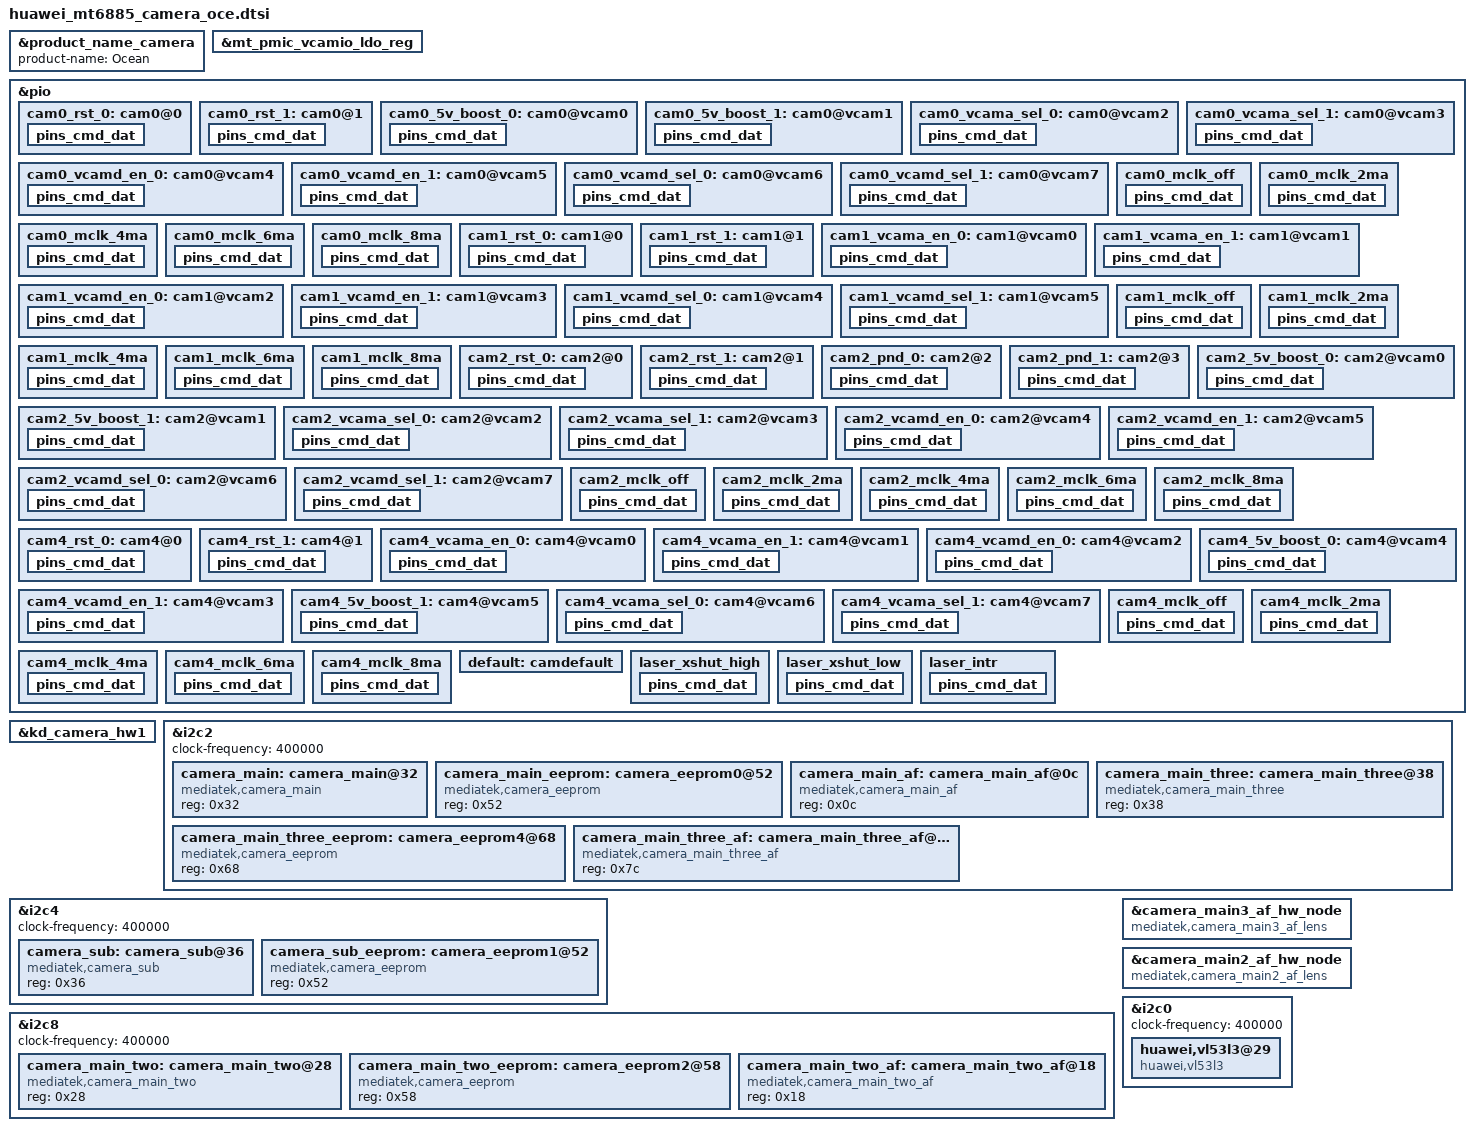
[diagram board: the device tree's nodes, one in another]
/*
 * Copyright (c) 2020 MediaTek Inc.
 *
 * This program is free software; you can redistribute it and/or modify
 * it under the terms of the GNU General Public License version 2 as
 * published by the Free Software Foundation.
 *
 * This program is distributed in the hope that it will be useful,
 * but WITHOUT ANY WARRANTY; without even the implied warranty of
 * MERCHANTABILITY or FITNESS FOR A PARTICULAR PURPOSE.  See the
 * GNU General Public License for more details.
 */

&product_name_camera {
	product-name = "Ocean";
};

&mt_pmic_vcamio_ldo_reg {
	regulator-min-microvolt = <1700000>;
	regulator-max-microvolt = <1900000>;
	regulator-default-on = <2>; /* 0:skip, 1: off, 2:on */
	regulator-boot-on;
};

/* CAMERA GPIO standardization */
&pio {
	/* Main Cam: cam0 GPIOs begin */
	cam0_rst_0: cam0@0 {
		pins_cmd_dat {
			pinmux = <PINMUX_GPIO143__FUNC_GPIO143>;
			slew-rate = <1>;
			output-low;
		};
	};
	cam0_rst_1: cam0@1 {
		pins_cmd_dat {
			pinmux = <PINMUX_GPIO143__FUNC_GPIO143>;
			slew-rate = <1>;
			output-high;
		};
	};

	/* bst_5v */
	cam0_5v_boost_0: cam0@vcam0 {
		pins_cmd_dat {
			pinmux = <PINMUX_GPIO81__FUNC_GPIO81>;
			slew-rate = <1>;
			output-low;
		};
	};
	cam0_5v_boost_1: cam0@vcam1 {
		pins_cmd_dat {
			pinmux = <PINMUX_GPIO81__FUNC_GPIO81>;
			slew-rate = <1>;
			output-high;
		};
	};

	cam0_vcama_sel_0: cam0@vcam2 {
		pins_cmd_dat {
			pinmux = <PINMUX_GPIO134__FUNC_GPIO134>;
			slew-rate = <1>;
			output-low;
		};
	};

	cam0_vcama_sel_1: cam0@vcam3 {
		pins_cmd_dat {
			pinmux = <PINMUX_GPIO134__FUNC_GPIO134>;
			slew-rate = <1>;
			output-high;
		};
	};

	cam0_vcamd_en_0: cam0@vcam4 {
		pins_cmd_dat {
			pinmux = <PINMUX_GPIO135__FUNC_GPIO135>;
			slew-rate = <1>;
			output-low;
		};
	};
	cam0_vcamd_en_1: cam0@vcam5 {
		pins_cmd_dat {
			pinmux = <PINMUX_GPIO135__FUNC_GPIO135>;
			slew-rate = <1>;
			output-high;
		};
	};

	cam0_vcamd_sel_0: cam0@vcam6 {
		pins_cmd_dat {
			pinmux = <PINMUX_GPIO138__FUNC_GPIO138>;
			slew-rate = <1>;
			output-low;
		};
	};
	cam0_vcamd_sel_1: cam0@vcam7 {
		pins_cmd_dat {
			pinmux = <PINMUX_GPIO138__FUNC_GPIO138>;
			slew-rate = <1>;
			output-high;
		};
	};

	cam0_mclk_off: cam0_mclk_off {
		pins_cmd_dat {
			pinmux = <PINMUX_GPIO149__FUNC_GPIO149>;
			drive-strength = <1>;
		};
	};
	cam0_mclk_2ma: cam0_mclk_2ma {
		pins_cmd_dat {
			pinmux = <PINMUX_GPIO149__FUNC_CMMCLK0>;
			drive-strength = <0>;
		};
	};
	cam0_mclk_4ma: cam0_mclk_4ma {
		pins_cmd_dat {
			pinmux = <PINMUX_GPIO149__FUNC_CMMCLK0>;
			drive-strength = <1>;
		};
	};
	cam0_mclk_6ma: cam0_mclk_6ma {
		pins_cmd_dat {
			pinmux = <PINMUX_GPIO149__FUNC_CMMCLK0>;
			drive-strength = <2>;
		};
	};
	cam0_mclk_8ma: cam0_mclk_8ma {
		pins_cmd_dat {
			pinmux = <PINMUX_GPIO149__FUNC_CMMCLK0>;
			drive-strength = <3>;
		};
	};
	/* Main Cam: cam0 GPIOs end */

	/* Sub(front) Cam: cam1 GPIOs begin */
	cam1_rst_0: cam1@0 {
		pins_cmd_dat {
			pinmux = <PINMUX_GPIO131__FUNC_GPIO131>;
			slew-rate = <1>;
			output-low;
		};
	};
	cam1_rst_1: cam1@1 {
		pins_cmd_dat {
			pinmux = <PINMUX_GPIO131__FUNC_GPIO131>;
			slew-rate = <1>;
			output-high;
		};
	};

	cam1_vcama_en_0: cam1@vcam0 {
		pins_cmd_dat {
			pinmux = <PINMUX_GPIO130__FUNC_GPIO130>;
			slew-rate = <1>;
			output-low;
		};
	};
	cam1_vcama_en_1: cam1@vcam1 {
		pins_cmd_dat {
			pinmux = <PINMUX_GPIO130__FUNC_GPIO130>;
			slew-rate = <1>;
			output-high;
		};
	};

	cam1_vcamd_en_0: cam1@vcam2 {
		pins_cmd_dat {
			pinmux = <PINMUX_GPIO134__FUNC_GPIO134>;
			slew-rate = <1>;
			output-low;
		};
	};
	cam1_vcamd_en_1: cam1@vcam3 {
		pins_cmd_dat {
			pinmux = <PINMUX_GPIO134__FUNC_GPIO134>;
			slew-rate = <1>;
			output-high;
		};
	};

	cam1_vcamd_sel_0: cam1@vcam4 {
		pins_cmd_dat {
			pinmux = <PINMUX_GPIO138__FUNC_GPIO138>;
			slew-rate = <1>;
			output-low;
		};
	};
	cam1_vcamd_sel_1: cam1@vcam5 {
		pins_cmd_dat {
			pinmux = <PINMUX_GPIO138__FUNC_GPIO138>;
			slew-rate = <1>;
			output-high;
		};
	};

	cam1_mclk_off: cam1_mclk_off {
		pins_cmd_dat {
			pinmux = <PINMUX_GPIO136__FUNC_GPIO136>;
			drive-strength = <1>;
		};
	};
	cam1_mclk_2ma: cam1_mclk_2ma {
		pins_cmd_dat {
			pinmux = <PINMUX_GPIO136__FUNC_CMMCLK3>;
			drive-strength = <0>;
		};
	};
	cam1_mclk_4ma: cam1_mclk_4ma {
		pins_cmd_dat {
			pinmux = <PINMUX_GPIO136__FUNC_CMMCLK3>;
			drive-strength = <1>;
		};
	};
	cam1_mclk_6ma: cam1_mclk_6ma {
		pins_cmd_dat {
			pinmux = <PINMUX_GPIO136__FUNC_CMMCLK3>;
			drive-strength = <2>;
		};
	};
	cam1_mclk_8ma: cam1_mclk_8ma {
		pins_cmd_dat {
			pinmux = <PINMUX_GPIO136__FUNC_CMMCLK3>;
			drive-strength = <3>;
		};
	};
	/* Sub(front) Cam: cam1 GPIOs end */

	/* Main2(wide) Cam: cam2 GPIOs begin */
	cam2_rst_0: cam2@0 {
		pins_cmd_dat {
			pinmux = <PINMUX_GPIO144__FUNC_GPIO144>;
			slew-rate = <1>;
			output-low;
		};
	};
	cam2_rst_1: cam2@1 {
		pins_cmd_dat {
			pinmux = <PINMUX_GPIO144__FUNC_GPIO144>;
			slew-rate = <1>;
			output-high;
		};
	};

	cam2_pnd_0: cam2@2 {
		pins_cmd_dat {
			pinmux = <PINMUX_GPIO130__FUNC_GPIO130>;
			slew-rate = <1>;
			output-low;
		};
	};
	cam2_pnd_1: cam2@3 {
		pins_cmd_dat {
			pinmux = <PINMUX_GPIO130__FUNC_GPIO130>;
			slew-rate = <1>;
			output-high;
		};
	};

	cam2_5v_boost_0: cam2@vcam0 {
		pins_cmd_dat {
			pinmux = <PINMUX_GPIO81__FUNC_GPIO81>;
			slew-rate = <1>;
			output-low;
		};
	};
	cam2_5v_boost_1: cam2@vcam1 {
		pins_cmd_dat {
			pinmux = <PINMUX_GPIO81__FUNC_GPIO81>;
			slew-rate = <1>;
			output-high;
		};
	};

	cam2_vcama_sel_0: cam2@vcam2 {
		pins_cmd_dat {
			pinmux = <PINMUX_GPIO137__FUNC_GPIO137>;
			slew-rate = <1>;
			output-low;
		};
	};
	cam2_vcama_sel_1: cam2@vcam3 {
		pins_cmd_dat {
			pinmux = <PINMUX_GPIO137__FUNC_GPIO137>;
			slew-rate = <1>;
			output-high;
		};
	};

	cam2_vcamd_en_0: cam2@vcam4 {
		pins_cmd_dat {
			pinmux = <PINMUX_GPIO134__FUNC_GPIO134>;
			slew-rate = <1>;
			output-low;
		};
	};
	cam2_vcamd_en_1: cam2@vcam5 {
		pins_cmd_dat {
			pinmux = <PINMUX_GPIO134__FUNC_GPIO134>;
			slew-rate = <1>;
			output-high;
		};
	};

	cam2_vcamd_sel_0: cam2@vcam6 {
		pins_cmd_dat {
			pinmux = <PINMUX_GPIO135__FUNC_GPIO135>;
			slew-rate = <1>;
			output-low;
		};
	};
	cam2_vcamd_sel_1: cam2@vcam7 {
		pins_cmd_dat {
			pinmux = <PINMUX_GPIO135__FUNC_GPIO135>;
			slew-rate = <1>;
			output-high;
		};
	};

	cam2_mclk_off: cam2_mclk_off {
		pins_cmd_dat {
			pinmux = <PINMUX_GPIO150__FUNC_GPIO150>;
			drive-strength = <1>;
		};
	};
	cam2_mclk_2ma: cam2_mclk_2ma {
		pins_cmd_dat {
			pinmux = <PINMUX_GPIO150__FUNC_CMMCLK1>;
			drive-strength = <0>;
		};
	};
	cam2_mclk_4ma: cam2_mclk_4ma {
		pins_cmd_dat {
			pinmux = <PINMUX_GPIO150__FUNC_CMMCLK1>;
			drive-strength = <1>;
		};
	};
	cam2_mclk_6ma: cam2_mclk_6ma {
		pins_cmd_dat {
			pinmux = <PINMUX_GPIO150__FUNC_CMMCLK1>;
			drive-strength = <2>;
		};
	};
	cam2_mclk_8ma: cam2_mclk_8ma {
		pins_cmd_dat {
			pinmux = <PINMUX_GPIO150__FUNC_CMMCLK1>;
			drive-strength = <3>;
		};
	};
	/* Main2(wide) Cam: cam2 GPIOs end */

	/* Main4(tele) Cam: cam4 GPIOs begin */
	cam4_rst_0: cam4@0 {
		pins_cmd_dat {
			pinmux = <PINMUX_GPIO145__FUNC_GPIO145>;
			slew-rate = <1>;
			output-low;
		};
	};
	cam4_rst_1: cam4@1 {
		pins_cmd_dat {
			pinmux = <PINMUX_GPIO145__FUNC_GPIO145>;
			slew-rate = <1>;
			output-high;
		};
	};

	cam4_vcama_en_0: cam4@vcam0 {
		pins_cmd_dat {
			pinmux = <PINMUX_GPIO134__FUNC_GPIO134>;
			slew-rate = <1>;
			output-low;
		};
	};
	cam4_vcama_en_1: cam4@vcam1 {
		pins_cmd_dat {
			pinmux = <PINMUX_GPIO134__FUNC_GPIO134>;
			slew-rate = <1>;
			output-high;
		};
	};

	cam4_vcamd_en_0: cam4@vcam2 {
		pins_cmd_dat {
			pinmux = <PINMUX_GPIO138__FUNC_GPIO138>;
			slew-rate = <1>;
			output-low;
		};
	};
	cam4_vcamd_en_1: cam4@vcam3 {
		pins_cmd_dat {
			pinmux = <PINMUX_GPIO138__FUNC_GPIO138>;
			slew-rate = <1>;
			output-high;
		};
	};

	cam4_5v_boost_0: cam4@vcam4 {
		pins_cmd_dat {
			pinmux = <PINMUX_GPIO81__FUNC_GPIO81>;
			slew-rate = <1>;
			output-low;
		};
	};
	cam4_5v_boost_1: cam4@vcam5 {
		pins_cmd_dat {
			pinmux = <PINMUX_GPIO81__FUNC_GPIO81>;
			slew-rate = <1>;
			output-high;
		};
	};

	cam4_vcama_sel_0: cam4@vcam6 {
		pins_cmd_dat {
			pinmux = <PINMUX_GPIO135__FUNC_GPIO135>;
			slew-rate = <1>;
			output-low;
		};
	};
	cam4_vcama_sel_1: cam4@vcam7 {
		pins_cmd_dat {
			pinmux = <PINMUX_GPIO135__FUNC_GPIO135>;
			slew-rate = <1>;
			output-high;
		};
	};

	cam4_mclk_off: cam4_mclk_off {
		pins_cmd_dat {
			pinmux = <PINMUX_GPIO151__FUNC_GPIO151>;
			drive-strength = <1>;
		};
	};
	cam4_mclk_2ma: cam4_mclk_2ma {
		pins_cmd_dat {
			pinmux = <PINMUX_GPIO151__FUNC_CMMCLK2>;
			drive-strength = <0>;
		};
	};
	cam4_mclk_4ma: cam4_mclk_4ma {
		pins_cmd_dat {
			pinmux = <PINMUX_GPIO151__FUNC_CMMCLK2>;
			drive-strength = <1>;
		};
	};
	cam4_mclk_6ma: cam4_mclk_6ma {
		pins_cmd_dat {
			pinmux = <PINMUX_GPIO151__FUNC_CMMCLK2>;
			drive-strength = <2>;
		};
	};
	cam4_mclk_8ma: cam4_mclk_8ma {
		pins_cmd_dat {
			pinmux = <PINMUX_GPIO151__FUNC_CMMCLK2>;
			drive-strength = <3>;
		};
	};
	/* Main4(tele) Cam: cam4 GPIOs end */

	default: camdefault {
	};

	/* laser GPIO begin */
	laser_xshut_high: laser_xshut_high {
		pins_cmd_dat {
			pinmux = <PINMUX_GPIO14__FUNC_GPIO14>;
			output-high;
		};
	};

	laser_xshut_low: laser_xshut_low {
		pins_cmd_dat {
			pinmux = <PINMUX_GPIO14__FUNC_GPIO14>;
			output-low;
		};
	};

	laser_intr: laser_intr {
		pins_cmd_dat {
			pinmux = <PINMUX_GPIO153__FUNC_GPIO153>;
			input-enable;
			bias-pull-up = <MTK_PUPD_SET_R1R0_01>;
		};
	};
	/* laser GPIO end */
};

&kd_camera_hw1 {
	pinctrl-names = "default",
		/* Main Cam: Cam0 begin */
		"cam0_rst0", "cam0_rst1",
		"cam0_5v_boost_0", "cam0_5v_boost_1",
		"cam0_vcama_sel_0", "cam0_vcama_sel_1",
		"cam0_vcamd_en_0", "cam0_vcamd_en_1",
		"cam0_vcamd_sel_0", "cam0_vcamd_sel_1",
		"cam0_mclk_off",
		"cam0_mclk_2mA", "cam0_mclk_4mA",
		"cam0_mclk_6mA", "cam0_mclk_8mA",
		/* Main Cam: Cam0 end */

		/* Sub(front) Cam: Cam1 begin */
		"cam1_rst0", "cam1_rst1",
		"cam1_vcama_en_0", "cam1_vcama_en_1",
		"cam1_vcamd_en_0", "cam1_vcamd_en_1",
		"cam1_vcamd_sel_0", "cam1_vcamd_sel_1",
		"cam1_mclk_off",
		"cam1_mclk_2mA", "cam1_mclk_4mA",
		"cam1_mclk_6mA", "cam1_mclk_8mA",
		/* Sub(front) Cam: Cam1 end */

		/* Main2(wide) Cam: Cam2 begin */
		"cam2_rst0", "cam2_rst1",
		"cam2_pnd0", "cam2_pnd1",
		"cam2_5v_boost_0", "cam2_5v_boost_1",
		"cam2_vcama_sel_0", "cam2_vcama_sel_1",
		"cam2_vcamd_en_0", "cam2_vcamd_en_1",
		"cam2_vcamd_sel_0", "cam2_vcamd_sel_1",
		"cam2_mclk_off",
		"cam2_mclk_2mA", "cam2_mclk_4mA",
		"cam2_mclk_6mA", "cam2_mclk_8mA",
		/* Main2(wide) Cam: Cam2 end */

		/* Main4(tele) Cam: Cam4 begin */
		"cam4_rst0", "cam4_rst1",
		"cam4_vcama_en_0", "cam4_vcama_en_1",
		"cam4_vcamd_en_0", "cam4_vcamd_en_1",
		"cam4_5v_boost_0", "cam4_5v_boost_1",
		"cam4_vcama_sel_0", "cam4_vcama_sel_1",
		"cam4_mclk_off",
		"cam4_mclk_2mA", "cam4_mclk_4mA",
		"cam4_mclk_6mA", "cam4_mclk_8mA";
		/* Main4(tele) Cam: Cam4 end */

	pinctrl-0 = <&default>;
	/* Main Cam: Cam0 begin */
	pinctrl-1 = <&cam0_rst_0>;
	pinctrl-2 = <&cam0_rst_1>;
	pinctrl-3 = <&cam0_5v_boost_0>;
	pinctrl-4 = <&cam0_5v_boost_1>;
	pinctrl-5 = <&cam0_vcama_sel_0>;
	pinctrl-6 = <&cam0_vcama_sel_1>;
	pinctrl-7 = <&cam0_vcamd_en_0>;
	pinctrl-8 = <&cam0_vcamd_en_1>;
	pinctrl-9 = <&cam0_vcamd_sel_0>;
	pinctrl-10 = <&cam0_vcamd_sel_1>;
	pinctrl-11 = <&cam0_mclk_off>;
	pinctrl-12 = <&cam0_mclk_2ma>;
	pinctrl-13 = <&cam0_mclk_4ma>;
	pinctrl-14 = <&cam0_mclk_6ma>;
	pinctrl-15 = <&cam0_mclk_8ma>;
	/* Sub(front) Cam: Cam1 begin */
	pinctrl-16 = <&cam1_rst_0>;
	pinctrl-17 = <&cam1_rst_1>;
	pinctrl-18 = <&cam1_vcama_en_0>;
	pinctrl-19 = <&cam1_vcama_en_1>;
	pinctrl-20 = <&cam1_vcamd_en_0>;
	pinctrl-21 = <&cam1_vcamd_en_1>;
	pinctrl-22 = <&cam1_vcamd_sel_0>;
	pinctrl-23 = <&cam1_vcamd_sel_1>;
	pinctrl-24 = <&cam1_mclk_off>;
	pinctrl-25 = <&cam1_mclk_2ma>;
	pinctrl-26 = <&cam1_mclk_4ma>;
	pinctrl-27 = <&cam1_mclk_6ma>;
	pinctrl-28 = <&cam1_mclk_8ma>;
	/* Main2(wide) Cam: Cam2 begin */
	pinctrl-29 = <&cam2_rst_0>;
	pinctrl-30 = <&cam2_rst_1>;
	pinctrl-31 = <&cam2_pnd_0>;
	pinctrl-32 = <&cam2_pnd_1>;
	pinctrl-33 = <&cam2_5v_boost_0>;
	pinctrl-34 = <&cam2_5v_boost_1>;
	pinctrl-35 = <&cam2_vcama_sel_0>;
	pinctrl-36 = <&cam2_vcama_sel_1>;
	pinctrl-37 = <&cam2_vcamd_en_0>;
	pinctrl-38 = <&cam2_vcamd_en_1>;
	pinctrl-39 = <&cam2_vcamd_sel_0>;
	pinctrl-40 = <&cam2_vcamd_sel_1>;
	pinctrl-41 = <&cam2_mclk_off>;
	pinctrl-42 = <&cam2_mclk_2ma>;
	pinctrl-43 = <&cam2_mclk_4ma>;
	pinctrl-44 = <&cam2_mclk_6ma>;
	pinctrl-45 = <&cam2_mclk_8ma>;
	/* Main4(tele) Cam: Cam4 begin */
	pinctrl-46 = <&cam4_rst_0>;
	pinctrl-47 = <&cam4_rst_1>;
	pinctrl-48 = <&cam4_vcama_en_0>;
	pinctrl-49 = <&cam4_vcama_en_1>;
	pinctrl-50 = <&cam4_vcamd_en_0>;
	pinctrl-51 = <&cam4_vcamd_en_1>;
	pinctrl-52 = <&cam4_5v_boost_0>;
	pinctrl-53 = <&cam4_5v_boost_1>;
	pinctrl-54 = <&cam4_vcama_sel_0>;
	pinctrl-55 = <&cam4_vcama_sel_1>;
	pinctrl-56 = <&cam4_mclk_off>;
	pinctrl-57 = <&cam4_mclk_2ma>;
	pinctrl-58 = <&cam4_mclk_4ma>;
	pinctrl-59 = <&cam4_mclk_6ma>;
	pinctrl-60 = <&cam4_mclk_8ma>;

	cam0_vcamio-supply = <&mt_pmic_vcamio_ldo_reg>;

	cam1_vcamio-supply = <&mt_pmic_vcamio_ldo_reg>;

	cam2_vcamio-supply = <&mt_pmic_vcamio_ldo_reg>;

	cam4_vcamio-supply = <&mt_pmic_vcamio_ldo_reg>;

	status = "okay";
};
/* CAMERA GPIO end */

/* CAMERA */
&i2c2 {
	#address-cells = <1>;
	#size-cells = <0>;
	clock-frequency = <400000>;
	camera_main:camera_main@32 {
		compatible = "mediatek,camera_main";
		reg = <0x32>;
		status = "okay";
	};
	camera_main_eeprom:camera_eeprom0@52 {
		compatible = "mediatek,camera_eeprom";
		reg = <0x52>;
		status = "okay";
	};
	camera_main_af:camera_main_af@0c {
		compatible = "mediatek,camera_main_af";
		reg = <0x0c>;
		status = "okay";
	};
	camera_main_three:camera_main_three@38 {
		compatible = "mediatek,camera_main_three";
		reg = <0x38>;
		status = "okay";
	};
	camera_main_three_eeprom:camera_eeprom4@68 {
		compatible = "mediatek,camera_eeprom";
		reg = <0x68>;
		status = "okay";
	};
	camera_main_three_af:camera_main_three_af@7c {
		compatible = "mediatek,camera_main_three_af";
		reg = <0x7c>;
		status = "okay";
	};
};

&i2c4 {
	#address-cells = <1>;
	#size-cells = <0>;
	clock-frequency = <400000>;
	camera_sub:camera_sub@36 {
		compatible = "mediatek,camera_sub";
		reg = <0x36>;
		status = "okay";
	};
	camera_sub_eeprom:camera_eeprom1@52 {
		compatible = "mediatek,camera_eeprom";
		reg = <0x52>;
		status = "okay";
	};
};

&i2c8 {
	#address-cells = <1>;
	#size-cells = <0>;
	clock-frequency = <400000>;
	camera_main_two:camera_main_two@28 {
		compatible = "mediatek,camera_main_two";
		reg = <0x28>;
		status = "okay";
	};
	camera_main_two_eeprom:camera_eeprom2@58 {
		compatible = "mediatek,camera_eeprom";
		reg = <0x58>;
		status = "okay";
	};
	camera_main_two_af:camera_main_two_af@18 {
		compatible = "mediatek,camera_main_two_af";
		reg = <0x18>;
		status = "okay";
	};
};

&camera_main3_af_hw_node {
	compatible = "mediatek,camera_main3_af_lens";
	status = "okay";
};

&camera_main2_af_hw_node {
	compatible = "mediatek,camera_main2_af_lens";
	status = "okay";
};

/* CAMERA end */

&i2c0 {
	#address-cells = <1>;
	#size-cells = <0>;
	clock-frequency = <400000>;
	huawei,vl53l3@29 {
		compatible = "huawei,vl53l3";
		reg = <0x29>;
		gpios = <&pio 14 0>,<&pio 153 0>;
		huawei,gpio-ctrl-types = "xsdn", "intr";
		pinctrl-names = "laser_xshut_high", "laser_xshut_low", "laser_intr";
		pinctrl-0 = <&laser_xshut_high>;
		pinctrl-1 = <&laser_xshut_low>;
		pinctrl-2 = <&laser_intr>;
		laser_state = <1>;
		status = "ok";
	};
};
